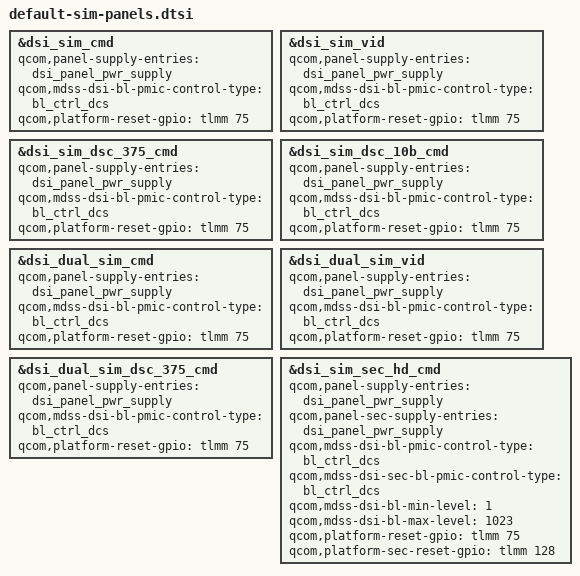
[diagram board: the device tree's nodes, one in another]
&dsi_sim_cmd {
	qcom,panel-supply-entries = <&dsi_panel_pwr_supply>;
	qcom,mdss-dsi-bl-pmic-control-type = "bl_ctrl_dcs";
	qcom,platform-reset-gpio = <&tlmm 75 0>;
};

&dsi_sim_vid {
	qcom,panel-supply-entries = <&dsi_panel_pwr_supply>;
	qcom,mdss-dsi-bl-pmic-control-type = "bl_ctrl_dcs";
	qcom,platform-reset-gpio = <&tlmm 75 0>;
};

&dsi_sim_dsc_375_cmd {
	qcom,panel-supply-entries = <&dsi_panel_pwr_supply>;
	qcom,mdss-dsi-bl-pmic-control-type = "bl_ctrl_dcs";
	qcom,platform-reset-gpio = <&tlmm 75 0>;
};

&dsi_sim_dsc_10b_cmd {
	qcom,panel-supply-entries = <&dsi_panel_pwr_supply>;
	qcom,mdss-dsi-bl-pmic-control-type = "bl_ctrl_dcs";
	qcom,platform-reset-gpio = <&tlmm 75 0>;
};

&dsi_dual_sim_cmd {
	qcom,panel-supply-entries = <&dsi_panel_pwr_supply>;
	qcom,mdss-dsi-bl-pmic-control-type = "bl_ctrl_dcs";
	qcom,platform-reset-gpio = <&tlmm 75 0>;
};

&dsi_dual_sim_vid {
	qcom,panel-supply-entries = <&dsi_panel_pwr_supply>;
	qcom,mdss-dsi-bl-pmic-control-type = "bl_ctrl_dcs";
	qcom,platform-reset-gpio = <&tlmm 75 0>;
};

&dsi_dual_sim_dsc_375_cmd {
	qcom,panel-supply-entries = <&dsi_panel_pwr_supply>;
	qcom,mdss-dsi-bl-pmic-control-type = "bl_ctrl_dcs";
	qcom,platform-reset-gpio = <&tlmm 75 0>;
};

&dsi_sim_sec_hd_cmd {
	qcom,panel-supply-entries = <&dsi_panel_pwr_supply>;
	qcom,panel-sec-supply-entries = <&dsi_panel_pwr_supply>;
	qcom,mdss-dsi-bl-pmic-control-type = "bl_ctrl_dcs";
	qcom,mdss-dsi-sec-bl-pmic-control-type = "bl_ctrl_dcs";
	qcom,mdss-dsi-bl-min-level = <1>;
	qcom,mdss-dsi-bl-max-level = <1023>;
	qcom,platform-reset-gpio = <&tlmm 75 0>;
	qcom,platform-sec-reset-gpio = <&tlmm 128 0>;
};
